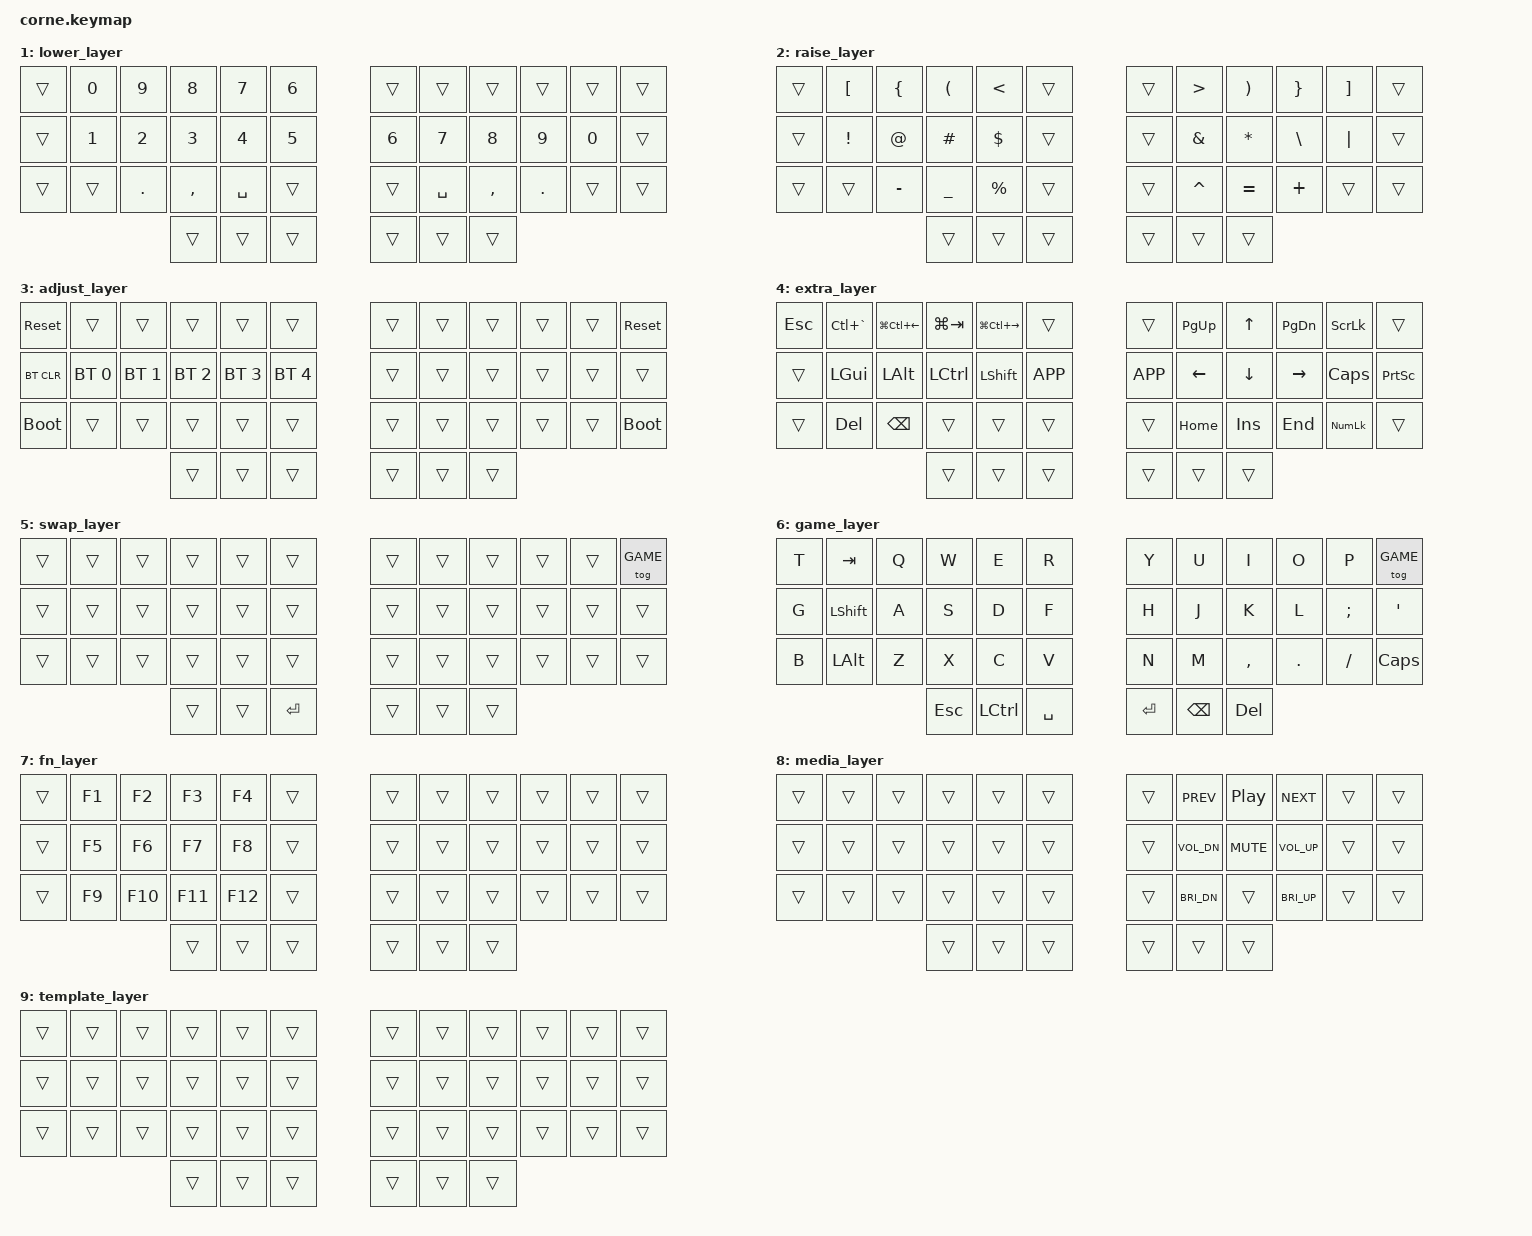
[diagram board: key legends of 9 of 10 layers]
// Copyright (c) 2022 The ZMK Contributors
// SPDX-License-Identifier: MIT

#include <behaviors.dtsi>
#include <dt-bindings/zmk/keys.h>
#include <dt-bindings/zmk/bt.h>

#define HRML(k1,k2,k3,k4) &ht LGUI k1   &ht LALT k2   &ht LCTRL k3  &ht LSHFT k4
#define HRMR(k1,k2,k3,k4) &ht RSHFT k1  &ht RCTRL k2  &ht RALT k3   &ht RGUI k4
#define TERM &kp LC(GRAVE)
#define TSK_V &kp LG(TAB)
#define DES_P &kp LG(LC(LEFT))
#define DES_N &kp LG(LC(RIGHT))

#define DEFAULT 0
#define LWR     1
#define RSE     2
#define ADJ     3
#define EXT     4
#define SWAP    5
#define GAME    6
#define FN      7
#define MEDIA   8

#define COMBO(NAME, BINDINGS, KEYPOS) \
    combo_##NAME { \
        timeout-ms = <50>; \
        bindings = <BINDINGS>; \
        key-positions = <KEYPOS>; \
        layers = <0>; \
    };

#define EXTRA_COMBO(NAME, BINDINGS, KEYPOS) \
    combo_##NAME { \
        timeout-ms = <50>; \
        bindings = <BINDINGS>; \
        key-positions = <KEYPOS>; \
        layers = <4>; \
    };

/ {
    behaviors {
        ht: homerow_mods {
            compatible = "zmk,behavior-hold-tap";
            label = "HOMEROW_MODS";
            #binding-cells = <2>;
            tapping_term_ms = <150>;
            quick_tap_ms = <250>;
            flavor = "tap-preferred";
            bindings = <&kp>, <&kp>;
        };
        tt: thumbrow_taps {
            compatible = "zmk,behavior-hold-tap";
            label = "THUMBROW_TAPS";
            #binding-cells = <2>;
            tapping_term_ms = <150>;
            quick_tap_ms = <250>;
            flavor = "tap-preferred";
            bindings = <&mo>, <&kp>;
        };
    };

    conditional_layers {
        compatible = "zmk,conditional-layers";
        adjust_layer {
            if-layers = <1 2>;
            then-layer = <3>;
        };
    };

    combos {
        compatible = "zmk,combos";
        COMBO(bt_clr_l,     &bt BT_CLR,    5 24)
        COMBO(bt_clr_r,     &bt BT_CLR,    6 35)
        COMBO(delete,       &kp DEL,       13 14)
        COMBO(backspace,    &kp BSPC,      14 15)
        COMBO(enter,        &kp RET,       15 16)
    };

    keymap {
        compatible = "zmk,keymap";

        default_layer {
// ╭───────┬───────┬───────┬───────┬───────┬───────╮     ╭───────┬───────┬───────┬───────┬───────┬───────╮
// |   [   |   Q   |   W   |   E   |   R   |   T   |     |   Y   |   U   |   I   |   O   |   P   |   ]   |
// |   `   |   A   |   S   |   D   |   F   |   G   |     |   H   |   J   |   K   |   L   |   ;   |   '   |
// |   -   |   Z   |   X   |   C   |   V   |   B   |     |   N   |   M   |   ,   |   .   |   /   |   =   |
// ╰───────┴───────┴───────┼───────┼───────┼───────┤     ├───────┼───────┼───────┼───────────────────────╯
//                         | ESC   |  TAB  |  SPC  |     |  ENT  |  BKSP |  DEL  |
//                         ╰───────┴───────┴───────╯     ╰───────┴───────┴───────╯
            bindings = <
        &kp LBKT   &kp Q       &kp W  &kp E       &kp R        &kp T             &kp Y        &kp U           &kp I      &kp O    &kp P     &kp RBKT
        &kp GRAVE  HRML(A,     S,     D,          F)           &kp G             &kp H        HRMR(J,         K,         L,       SEMI)     &kp SQT
        &kp MINUS  &tt SWAP Z  &kp X  &kp C       &kp V        &kp B             &kp N        &kp M           &kp COMMA  &kp DOT  &kp FSLH  &kp EQUAL
                                      &tt FN ESC  &tt EXT TAB  &tt LWR SPACE     &tt RSE RET  &tt MEDIA BSPC  &tt FN DEL
            >;
        };

        lower_layer {
// ╭───────┬───────┬───────┬───────┬───────┬───────╮     ╭───────┬───────┬───────┬───────┬───────┬───────╮
// |       |   0   |   9   |   8   |   7   |   6   |     |       |       |       |       |       |       |
// |       |   1   |   2   |   3   |   4   |   5   |     |   6   |   7   |   8   |   9   |   0   |       |
// |       |       |   .   |   ,   |  " "  |       |     |       |  " "  |   ,   |   .   |       |       |
// ╰───────┴───────┴───────┼───────┼───────┼───────┤     ├───────┼───────┼───────┼───────────────────────╯
//                         |       |       |       |     |       |       |       |
//                         ╰───────┴───────┴───────╯     ╰───────┴───────┴───────╯
            bindings = <
        &trans  &kp N0   &kp N9     &kp N8  &kp N7     &kp N6     &trans  &trans     &trans     &trans   &trans  &trans
        &trans  &kp N1   &kp N2     &kp N3  &kp N4     &kp N5     &kp N6  &kp N7     &kp N8     &kp N9   &kp N0  &trans
        &trans  &trans  &kp DOT  &kp COMMA  &kp SPACE  &trans     &trans  &kp SPACE  &kp COMMA  &kp DOT  &trans  &trans
                                    &trans  &trans     &trans     &trans  &trans     &trans
            >;
        };

        raise_layer {
// ╭───────┬───────┬───────┬───────┬───────┬───────╮     ╭───────┬───────┬───────┬───────┬───────┬───────╮
// |       |   [   |   {   |   (   |   <   |       |     |       |   >   |   )   |   }   |   ]   |       |
// |       |   !   |   @   |   #   |   $   |       |     |       |   &   |   *   |   \   |   |   |       |
// |       |       |   -   |   _   |   %   |       |     |       |   ^   |   =   |   +   |       |       |
// ╰───────┴───────┴───────┼───────┼───────┼───────┤     ├───────┼───────┼───────┼───────────────────────╯
//                         |       |       |       |     |       |       |       |
//                         ╰───────┴───────┴───────╯     ╰───────┴───────┴───────╯
            bindings = <
        &trans  &kp LBKT  &kp LBRC   &kp LPAR   &kp LT     &trans     &trans  &kp GT     &kp RPAR   &kp RBRC  &kp RBKT  &trans
        &trans  &kp EXCL  &kp AT     &kp HASH   &kp DLLR   &trans     &trans  &kp AMPS   &kp ASTRK  &kp BSLH  &kp PIPE  &trans
        &trans  &trans    &kp MINUS  &kp UNDER  &kp PRCNT  &trans     &trans  &kp CARET  &kp EQUAL  &kp PLUS  &trans    &trans
                                     &trans     &trans     &trans     &trans  &trans     &trans
            >;
        };

        adjust_layer {
// ╭───────┬───────┬───────┬───────┬───────┬───────╮     ╭───────┬───────┬───────┬───────┬───────┬───────╮
// | RESET |       |       |       |       |       |     |       |       |       |       |       | RESET |
// | BTCLR |  BT0  |  BT1  |  BT2  |  BT3  |  BT4  |     |       |       |       |       |       |       |
// | BOOTL |       |       |       |       |       |     |       |       |       |       |       | BOOTL |
// ╰───────┴───────┴───────┼───────┼───────┼───────┤     ├───────┼───────┼───────┼───────────────────────╯
//                         |       |       |       |     |       |       |       |
//                         ╰───────┴───────┴───────╯     ╰───────┴───────┴───────╯
            bindings = <
        &sys_reset   &trans        &trans        &trans        &trans        &trans           &trans  &trans  &trans  &trans  &trans  &sys_reset
        &bt BT_CLR   &bt BT_SEL 0  &bt BT_SEL 1  &bt BT_SEL 2  &bt BT_SEL 3  &bt BT_SEL 4     &trans  &trans  &trans  &trans  &trans  &trans
        &bootloader  &trans        &trans        &trans        &trans        &trans           &trans  &trans  &trans  &trans  &trans  &bootloader
                                                 &trans        &trans        &trans           &trans  &trans  &trans
            >;
        };

        extra_layer {
// ╭───────┬───────┬───────┬───────┬───────┬───────╮     ╭───────┬───────┬───────┬───────┬───────┬───────╮
// |  ESC  | TRMNL | <DESK | TASKS | DESK> |       |     |       | PG UP |  UP   | PG DN | SLCK  |       |
// |       |  GUI  |  ALT  | CTRL  | SHIFT |  APP  |     |  APP  | LEFT  | DOWN  | RIGHT | CLCK  | PRN S |
// |       |  DEL  | BSPC  |       |       |       |     |       | HOME  |  INS  |  END  | NLCK  |       |
// ╰───────┴───────┴───────┼───────┼───────┼───────┤     ├───────┼───────┼───────┼───────────────────────╯
//                         |       |       |       |     |       |       |       |
//                         ╰───────┴───────┴───────╯     ╰───────┴───────┴───────╯
            bindings = <
        &kp ESC  TERM      DES_P     TSK_V      DES_N      &trans        &trans     &kp PG_UP  &kp UP    &kp PG_DN  &kp SLCK     &trans
        &trans   &kp LGUI  &kp LALT  &kp LCTRL  &kp LSHFT  &kp K_APP     &kp K_APP  &kp LEFT   &kp DOWN  &kp RIGHT  &kp CLCK     &kp PSCRN
        &trans   &kp DEL   &kp BSPC  &trans     &trans     &trans        &trans     &kp HOME   &kp INS   &kp END    &kp KP_NLCK  &trans
                                     &trans     &trans     &trans        &trans     &trans     &trans
            >;
        };

        swap_layer {
// ╭───────┬───────┬───────┬───────┬───────┬───────╮     ╭───────┬───────┬───────┬───────┬───────┬───────╮
// |       |       |       |       |       |       |     |       |       |       |       |       | GAME  |
// |       |       |       |       |       |       |     |       |       |       |       |       |       |
// |       |       |       |       |       |       |     |       |       |       |       |       |       |
// ╰───────┴───────┴───────┼───────┼───────┼───────┤     ├───────┼───────┼───────┼───────────────────────╯
//                         |       |       |  ENT  |     |       |       |       |
//                         ╰───────┴───────┴───────╯     ╰───────┴───────┴───────╯
            bindings = <
        &trans  &trans  &trans  &trans  &trans  &trans      &trans  &trans  &trans  &trans  &trans  &tog GAME
        &trans  &trans  &trans  &trans  &trans  &trans      &trans  &trans  &trans  &trans  &trans  &trans
        &trans  &trans  &trans  &trans  &trans  &trans      &trans  &trans  &trans  &trans  &trans  &trans
                                &trans  &trans  &kp RET     &trans  &trans  &trans
            >;
        };

        game_layer {
// ╭───────┬───────┬───────┬───────┬───────┬───────╮     ╭───────┬───────┬───────┬───────┬───────┬───────╮
// |   T   |  TAB  |   Q   |   W   |   E   |   R   |     |   Y   |   U   |   I   |   O   |   P   | GAME  |
// |   G   | SHIFT |   A   |   S   |   D   |   F   |     |   H   |   J   |   K   |   L   |   ;   |   '   |
// |   B   |  ALT  |   Z   |   X   |   C   |   V   |     |   N   |   M   |   ,   |   .   |   /   | CAPS  |
// ╰───────┴───────┴───────┼───────┼───────┼───────┤     ├───────┼───────┼───────┼───────────────────────╯
//                         |  ESC  | CTRL  | SPACE |     |  ENT  | BKSP  |  DEL  |
//                         ╰───────┴───────┴───────╯     ╰───────┴───────┴───────╯
            bindings = <
        &kp T  &kp TAB    &kp Q  &kp W    &kp E      &kp R         &kp Y    &kp U     &kp I      &kp O    &kp P     &tog GAME
        &kp G  &kp LSHFT  &kp A  &kp S    &kp D      &kp F         &kp H    &kp J     &kp K      &kp L    &kp SEMI  &kp SQT
        &kp B  &kp LALT   &kp Z  &kp X    &kp C      &kp V         &kp N    &kp M     &kp COMMA  &kp DOT  &kp FSLH  &kp CLCK
                                 &kp ESC  &kp LCTRL  &kp SPACE     &kp RET  &kp BSPC  &kp DEL
            >;
        };

        fn_layer {
// ╭───────┬───────┬───────┬───────┬───────┬───────╮     ╭───────┬───────┬───────┬───────┬───────┬───────╮ 
// |       |  F1   |  F2   |  F3   |  F4   |       |     |       |       |       |       |       |       |
// |       |  F5   |  F6   |  F7   |  F8   |       |     |       |       |       |       |       |       |
// |       |  F9   |  F10  |  F11  |  F12  |       |     |       |       |       |       |       |       |
// ╰───────┴───────┴───────┼───────┼───────┼───────┤     ├───────┼───────┼───────┼───────────────────────╯
//                         |       |       |       |     |       |       |       |
//                         ╰───────┴───────┴───────╯     ╰───────┴───────┴───────╯
            bindings = <
        &trans  &kp F1  &kp F2   &kp F3   &kp F4   &trans     &trans  &trans  &trans  &trans  &trans  &trans
        &trans  &kp F5  &kp F6   &kp F7   &kp F8   &trans     &trans  &trans  &trans  &trans  &trans  &trans
        &trans  &kp F9  &kp F10  &kp F11  &kp F12  &trans     &trans  &trans  &trans  &trans  &trans  &trans
                                 &trans   &trans   &trans     &trans  &trans  &trans
            >;
        };

        media_layer {
// ╭───────┬───────┬───────┬───────┬───────┬───────╮     ╭───────┬───────┬───────┬───────┬───────┬───────╮
// |       |       |       |       |       |       |     |       |  <<   |  P\P  |  >>   |       |       |
// |       |       |       |       |       |       |     |       | VOL-  | MUTE  | VOL+  |       |       |
// |       |       |       |       |       |       |     |       | BRI-  |       | BRI+  |       |       |
// ╰───────┴───────┴───────┼───────┼───────┼───────┤     ├───────┼───────┼───────┼───────────────────────╯
//                         |       |       |       |     |       |       |       |
//                         ╰───────┴───────┴───────╯     ╰───────┴───────┴───────╯
            bindings = <
        &trans  &trans  &trans  &trans  &trans  &trans     &trans  &kp C_PREV    &kp C_PP    &kp C_NEXT    &trans  &trans
        &trans  &trans  &trans  &trans  &trans  &trans     &trans  &kp C_VOL_DN  &kp C_MUTE  &kp C_VOL_UP  &trans  &trans
        &trans  &trans  &trans  &trans  &trans  &trans     &trans  &kp C_BRI_DN  &trans      &kp C_BRI_UP  &trans  &trans
                                &trans  &trans  &trans     &trans  &trans        &trans
            >;
        };

        template_layer {
// ╭───────┬───────┬───────┬───────┬───────┬───────╮     ╭───────┬───────┬───────┬───────┬───────┬───────╮
// |       |       |       |       |       |       |     |       |       |       |       |       |       |
// |       |       |       |       |       |       |     |       |       |       |       |       |       |
// |       |       |       |       |       |       |     |       |       |       |       |       |       |
// ╰───────┴───────┴───────┼───────┼───────┼───────┤     ├───────┼───────┼───────┼───────────────────────╯
//                         |       |       |       |     |       |       |       |
//                         ╰───────┴───────┴───────╯     ╰───────┴───────┴───────╯
            bindings = <
        &trans  &trans  &trans  &trans  &trans  &trans     &trans  &trans  &trans  &trans  &trans  &trans
        &trans  &trans  &trans  &trans  &trans  &trans     &trans  &trans  &trans  &trans  &trans  &trans
        &trans  &trans  &trans  &trans  &trans  &trans     &trans  &trans  &trans  &trans  &trans  &trans
                                &trans  &trans  &trans     &trans  &trans  &trans
            >;
        };
    };
};
